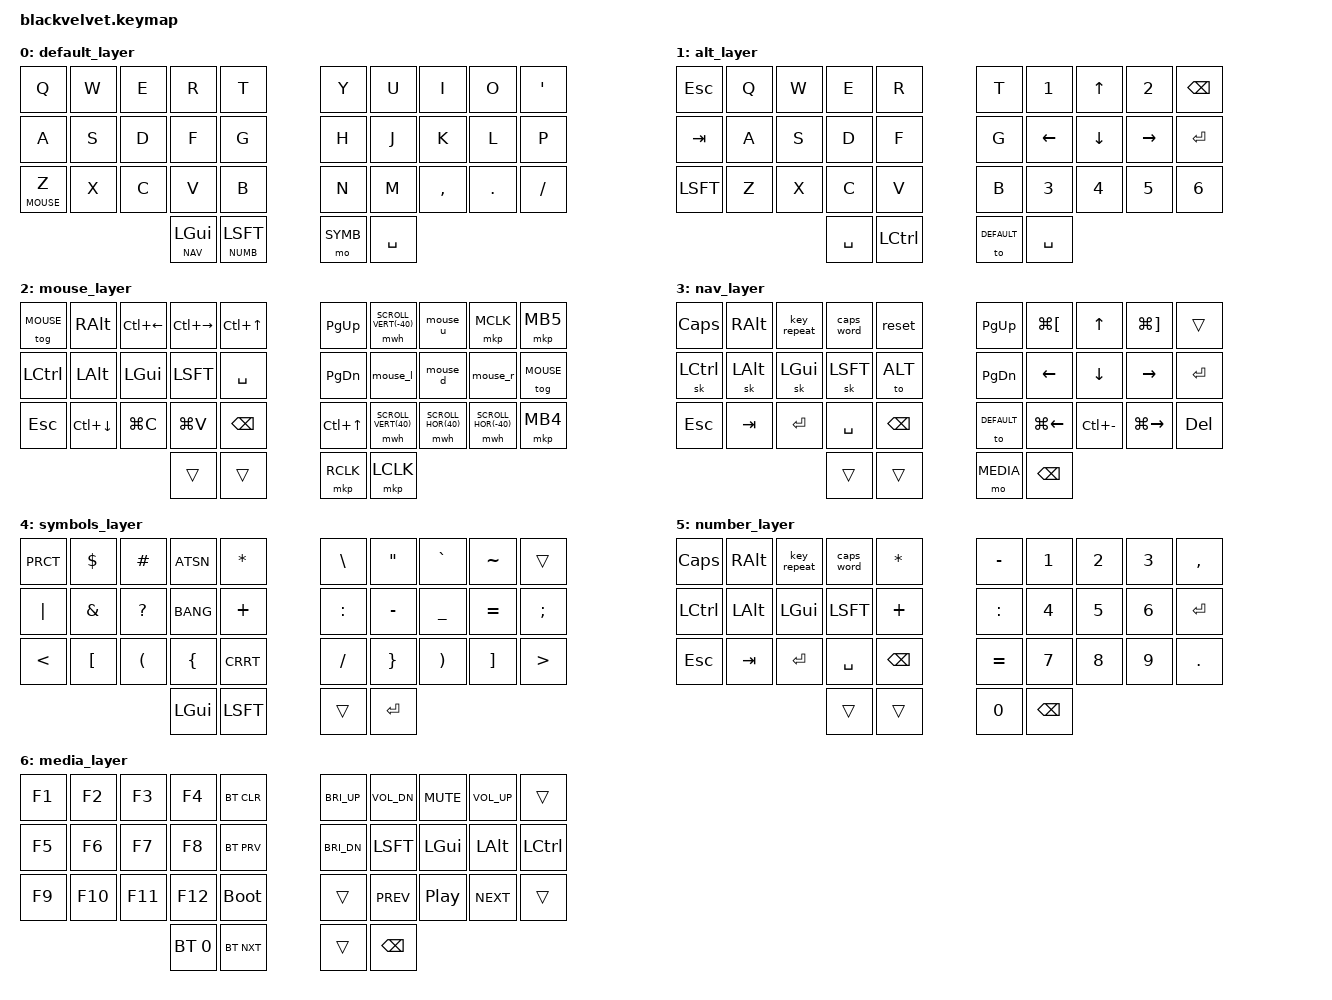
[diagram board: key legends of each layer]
/*
 * Copyright (c) 2020 The ZMK Contributors
 *
 * SPDX-License-Identifier: MIT
 */

#include <behaviors.dtsi>
#include <dt-bindings/zmk/keys.h>
#include <dt-bindings/zmk/bt.h>
#include <dt-bindings/zmk/mouse.h>

#define DEFAULT 0
#define ALT 1
#define MOUSE 2
#define NAV 3
#define SYMB 4
#define NUMB 5
#define MEDIA 6

&sk {
  release-after-ms = <500>;
  quick-release;
};

&sl {
  release-after-ms = <500>;
};

&lt {
  flavor = "hold-preferred";
};

&mmv {
    time-to-max-speed-ms = <1000>;
    acceleration-exponent=<1>;
};

&mwh {
    time-to-max-speed-ms = <1000>;
    acceleration-exponent=<1>;
};

/ { 

  combos {
      compatible = "zmk,combos";
      combo_esc {
          timeout-ms = <50>;
          key-positions = <32 33>;
          bindings = <&kp ESC>;
      };
      combo_tab {
          timeout-ms = <50>;
          key-positions = <30 31>;
          bindings = <&kp TAB>;
      };
  };

  behaviors {
    ml: mod_layer {
      compatible = "zmk,behavior-hold-tap";
      label = "MOD_LAYER";
      #binding-cells = <2>;
      flavor = "hold-preferred";
      tapping-term-ms = <150>;
      bindings = <&mo>, <&sk>;
    };
    mo_tog: behavior_mo_tog {
      compatible = "zmk,behavior-hold-tap";
      label = "mo_tog";
      #binding-cells = <2>;
      flavor = "hold-preferred";
      tapping-term-ms = <200>;
      bindings = <&mo>, <&tog>;
    };
    tlt: tap_layer_tap {
      compatible = "zmk,behavior-hold-tap";
      label = "tap_lt";
      #binding-cells = <2>;
      flavor = "tap-preferred";
      tapping-term-ms = <200>;
      bindings = <&mo>, <&kp>;
    };
    dlt: double_layer_tap {
      compatible = "zmk,behavior-tap-dance";
      label = "DOUBLE_LAYER_TAP";
      #binding-cells = <0>;
      tapping-term-ms = <200>;
      bindings = <&kp CMMA>, <&to MOUSE>;
    };
    lit: left_inner_thumb {
      compatible = "zmk,behavior-tap-dance";
      label = "LEFT_INNER_THUMB";
      #binding-cells = <0>;
      tapping-term-ms = <200>;
      bindings = <&ml NUMB LSFT>, <&mo MOUSE>;
    };
    mouse_l: mouse_left {
      compatible = "zmk,behavior-mod-morph";
      label = "MOUSE_LEFT";
      #binding-cells = <0>;
      bindings = <&mmv MOVE_HOR(-5000)>, <&mmv MOVE_HOR(-2000)>;
      mods = <(MOD_LSFT|MOD_RSFT)>;
    };
    mouse_r: mouse_right {
      compatible = "zmk,behavior-mod-morph";
      label = "MOUSE_RIGHT";
      #binding-cells = <0>;
      bindings = <&mmv MOVE_HOR(5000)>, <&mmv MOVE_HOR(2000)>;
      mods = <(MOD_LSFT|MOD_RSFT)>;
    };
    mouse_u: mouse_up {
      compatible = "zmk,behavior-mod-morph";
      label = "MOUSE_UP";
      #binding-cells = <0>;
      bindings = <&mmv MOVE_VERT(-5000)>, <&mmv MOVE_VERT(-2000)>;
      mods = <(MOD_LSFT|MOD_RSFT)>;
    };
    mouse_d: mouse_down {
      compatible = "zmk,behavior-mod-morph";
      label = "MOUSE_DOWN";
      #binding-cells = <0>;
      bindings = <&mmv MOVE_VERT(5000)>, <&mmv MOVE_VERT(2000)>;
      mods = <(MOD_LSFT|MOD_RSFT)>;
    };
  };

  keymap {
    compatible = "zmk,keymap";
    default_layer {
      bindings = <
        &kp Q  &kp W  &kp E  &kp R  &kp T           &kp Y  &kp U  &kp I  &kp O  &kp QUOT 
        &kp A  &kp S  &kp D  &kp F  &kp G           &kp H  &kp J  &kp K  &kp L  &kp P
        &tlt MOUSE Z  &kp X  &kp C  &kp V  &kp B    &kp N  &kp M  &kp CMMA  &kp DOT  &kp FSLH
              &ml NAV LGUI  &ml NUMB LSFT           &mo SYMB  &kp SPC
      >;
    };

    alt_layer {
      bindings = <
        &kp ESC  &kp Q  &kp W  &kp E  &kp R             &kp T  &kp N1  &kp UP  &kp N2  &kp BKSP 
        &kp TAB  &kp A  &kp S  &kp D  &kp F             &kp G  &kp LEFT  &kp DOWN  &kp RIGHT  &kp ENTER
        &kp LSFT  &kp Z  &kp X  &kp C  &kp V            &kp B  &kp N3  &kp N4  &kp N5  &kp N6
                          &kp SPC  &kp LCTL             &to DEFAULT  &kp SPC
        >;
    };

    mouse_layer {
      bindings = <
        &tog  MOUSE  &kp RALT  &kp LC(LEFT)  &kp LC(RIGHT)  &kp LC(UP)        &kp PG_UP  &mwh SCROLL_VERT(-40)  &mouse_u  &mkp MCLK  &mkp MB5 
        &kp LCTL  &kp LALT  &kp LGUI  &kp LSFT  &kp SPC                       &kp PG_DN  &mouse_l  &mouse_d  &mouse_r  &tog MOUSE
        &kp ESC  &kp LC(DOWN)  &kp LG(C)  &kp LG(V)  &kp BKSP                 &kp LC(UP)  &mwh SCROLL_VERT(40)  &mwh SCROLL_HOR(40)  &mwh SCROLL_HOR(-40)  &mkp MB4 
                                    &trans  &trans                            &mkp RCLK  &mkp LCLK
      >;
    }; 

    nav_layer {
      bindings = <
        &kp CAPS  &kp RALT  &key_repeat  &caps_word  &reset     &kp PG_UP  &kp LG(LBKT)  &kp UP  &kp LG(RBKT)  &trans 
        &sk LCTL  &sk LALT  &sk LGUI  &sk LSFT  &to ALT         &kp PG_DN  &kp LEFT  &kp DOWN  &kp RIGHT  &kp ENTER
        &kp ESC  &kp TAB  &kp ENTER  &kp SPC  &kp BKSP          &to DEFAULT  &kp LG(LEFT)  &kp LC(MINUS)  &kp LG(RIGHT)  &kp DEL 
                                        &trans  &trans          &mo MEDIA  &kp BKSP
      >;
    };
      
    symbols_layer {
      bindings = <
        &kp PRCT  &kp DLLR  &kp HASH  &kp ATSN  &kp STAR        &kp BSLH  &kp DQT &kp GRAV &kp TILDE &trans
        &kp PIPE  &kp AMPS  &kp QMARK  &kp BANG  &kp PLUS       &kp COLON  &kp MINUS  &kp UNDER  &kp EQUAL  &kp SEMI
        &kp LT  &kp LBKT  &kp LPAR  &kp LBRC  &kp CRRT          &kp FSLH  &kp RBRC  &kp RPAR  &kp RBKT  &kp GT
                                    &kp LGUI  &kp LSFT          &trans  &kp ENTER 
      >;
    };	

    number_layer {
      bindings = <
        &kp CAPS  &kp RALT  &key_repeat  &caps_word  &kp STAR       &kp MINUS  &kp N1  &kp N2  &kp N3  &kp CMMA
        &kp LCTL  &kp LALT  &kp LGUI  &kp LSFT  &kp PLUS            &kp COLON  &kp N4  &kp N5  &kp N6  &kp ENTER 
        &kp ESC  &kp TAB  &kp ENTER  &kp SPC  &kp BKSP              &kp EQUAL  &kp N7  &kp N8  &kp N9  &kp DOT   
                                        &trans  &trans              &kp N0 &kp BKSP
      >;
    };

    media_layer {
      bindings = <
        &kp F1  &kp F2  &kp F3  &kp F4  &bt BT_CLR            &kp C_BRI_UP  &kp C_VOL_DN  &kp C_MUTE  &kp C_VOL_UP  &trans
        &kp F5  &kp F6  &kp F7  &kp F8  &bt BT_PRV            &kp C_BRI_DN  &kp LSFT  &kp LGUI  &kp LALT  &kp LCTL 
        &kp F9  &kp F10  &kp F11  &kp F12  &bootloader        &trans  &kp C_PREV  &kp C_PP  &kp C_NEXT  &trans   
                                &bt BT_SEL 0 &bt BT_NXT       &trans &kp BKSP
      >;
    };
  };
};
